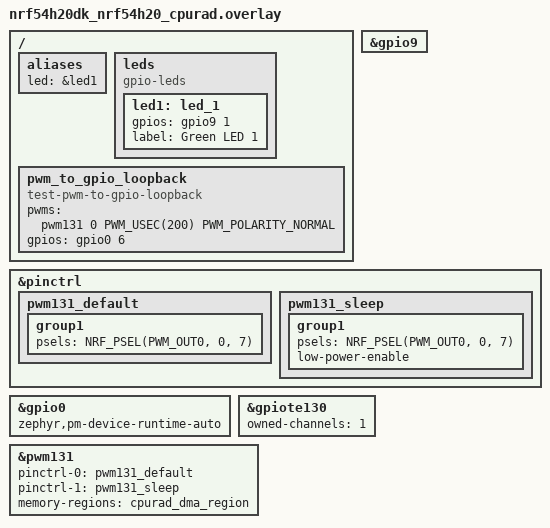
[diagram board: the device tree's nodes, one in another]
/*
 * Copyright (c) 2024 Nordic Semiconductor ASA
 *
 * SPDX-License-Identifier: LicenseRef-Nordic-5-Clause
 */

#include <zephyr/dt-bindings/pwm/pwm.h>
#include <zephyr/dt-bindings/gpio/nordic-nrf-gpio.h>

/* Test requires wire connection between:
 *  - PWM131 OUT[0] at P0.07
 *  - GPIO input at P0.06
 */

/ {
	aliases {
		led = &led1;
	};

	leds {
		compatible = "gpio-leds";

		led1: led_1 {
			gpios = <&gpio9 1 GPIO_ACTIVE_HIGH>;
			label = "Green LED 1";
		};
	};

	pwm_to_gpio_loopback: pwm_to_gpio_loopback {
		compatible = "test-pwm-to-gpio-loopback";
		pwms = <&pwm131 0 PWM_USEC(200) PWM_POLARITY_NORMAL>;
		gpios = <&gpio0 6 GPIO_ACTIVE_HIGH>;
	};
};

&gpio9 {
	status = "okay";
};

&pinctrl {
	/omit-if-no-ref/ pwm131_default: pwm131_default {
		group1 {
			psels = <NRF_PSEL(PWM_OUT0, 0, 7)>;
		};
	};

	/omit-if-no-ref/ pwm131_sleep: pwm131_sleep {
		group1 {
			psels = <NRF_PSEL(PWM_OUT0, 0, 7)>;
			low-power-enable;
		};
	};
};

&gpio0 {
	status = "okay";
	zephyr,pm-device-runtime-auto;
};

&gpiote130 {
	status = "okay";
	owned-channels = <1>;
};

&pwm131 {
	status = "okay";
	pinctrl-0 = <&pwm131_default>;
	pinctrl-1 = <&pwm131_sleep>;
	pinctrl-names = "default", "sleep";
	memory-regions = <&cpurad_dma_region>;
};
